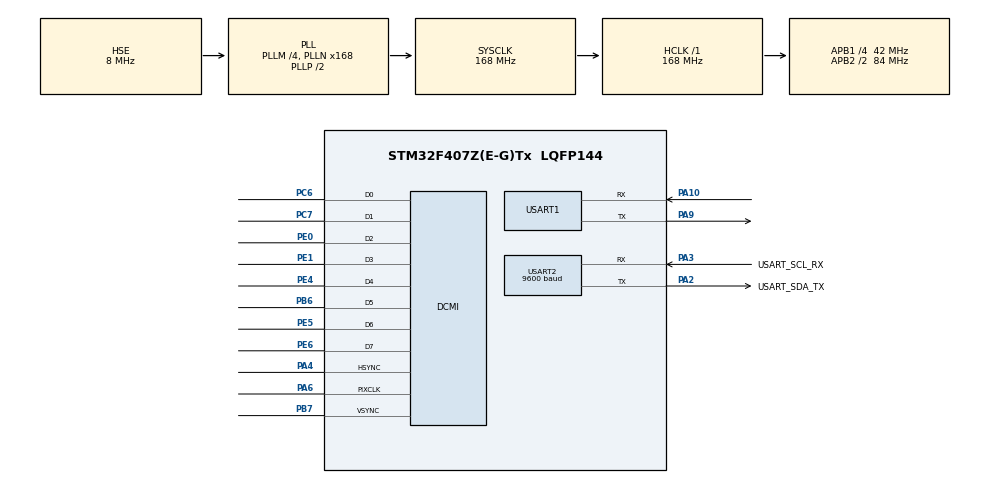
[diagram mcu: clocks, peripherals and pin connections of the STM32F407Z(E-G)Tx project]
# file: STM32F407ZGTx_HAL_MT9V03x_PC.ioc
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DCMI.JPEGMode=DCMI_JPEG_DISABLE
DCMI.PCKPolarity=DCMI_PCKPOLARITY_RISING
Dma.DCMI.0.Direction=DMA_PERIPH_TO_MEMORY
Dma.DCMI.0.FIFOMode=DMA_FIFOMODE_ENABLE
Dma.DCMI.0.FIFOThreshold=DMA_FIFO_THRESHOLD_FULL
Dma.DCMI.0.Instance=DMA2_Stream1
Dma.DCMI.0.MemBurst=DMA_MBURST_SINGLE
Dma.DCMI.0.MemDataAlignment=DMA_MDATAALIGN_WORD
Dma.DCMI.0.MemInc=DMA_MINC_ENABLE
Dma.DCMI.0.Mode=DMA_CIRCULAR
Dma.DCMI.0.PeriphBurst=DMA_PBURST_SINGLE
Dma.DCMI.0.PeriphDataAlignment=DMA_PDATAALIGN_WORD
Dma.DCMI.0.PeriphInc=DMA_PINC_DISABLE
Dma.DCMI.0.Priority=DMA_PRIORITY_VERY_HIGH
Dma.Request0=DCMI
Mcu.Family=STM32F4
Mcu.Name=STM32F407Z(E-G)Tx
Mcu.Package=LQFP144
NVIC.DCMI_IRQn=true\:0\:0\:false\:true\:true\:1\:true\:true\:true
NVIC.DMA2_Stream1_IRQn=true\:0\:0\:false\:false\:true\:false\:true\:true
NVIC.PriorityGroup=NVIC_PRIORITYGROUP_4
NVIC.USART2_IRQn=true\:0\:0\:false\:true\:true\:2\:true\:true\:true
PA10.Mode=Asynchronous
PA10.Signal=USART1_RX
PA13.Mode=Serial_Wire
PA13.Signal=SYS_JTMS-SWDIO
PA14.Mode=Serial_Wire
PA14.Signal=SYS_JTCK-SWCLK
PA2.GPIO_Label=USART_SDA_TX
PA2.Mode=Asynchronous
PA2.Signal=USART2_TX
PA3.GPIO_Label=USART_SCL_RX
PA3.Mode=Asynchronous
PA3.Signal=USART2_RX
PA4.Mode=Slave_8_bits_External_Synchro
PA4.Signal=DCMI_HSYNC
PA6.Mode=Slave_8_bits_External_Synchro
PA6.Signal=DCMI_PIXCLK
PA9.Mode=Asynchronous
PA9.Signal=USART1_TX
PB6.Mode=Slave_8_bits_External_Synchro
PB6.Signal=DCMI_D5
PB7.Mode=Slave_8_bits_External_Synchro
PB7.Signal=DCMI_VSYNC
PC14-OSC32_IN.Mode=LSE-External-Oscillator
PC14-OSC32_IN.Signal=RCC_OSC32_IN
PC15-OSC32_OUT.Mode=LSE-External-Oscillator
PC15-OSC32_OUT.Signal=RCC_OSC32_OUT
PC6.Mode=Slave_8_bits_External_Synchro
PC6.Signal=DCMI_D0
PC7.Mode=Slave_8_bits_External_Synchro
PC7.Signal=DCMI_D1
PE0.Mode=Slave_8_bits_External_Synchro
PE0.Signal=DCMI_D2
PE1.Mode=Slave_8_bits_External_Synchro
PE1.Signal=DCMI_D3
PE4.Mode=Slave_8_bits_External_Synchro
PE4.Signal=DCMI_D4
PE5.Mode=Slave_8_bits_External_Synchro
PE5.Signal=DCMI_D6
PE6.Mode=Slave_8_bits_External_Synchro
PE6.Signal=DCMI_D7
PH0-OSC_IN.Mode=HSE-External-Oscillator
PH0-OSC_IN.Signal=RCC_OSC_IN
PH1-OSC_OUT.Mode=HSE-External-Oscillator
PH1-OSC_OUT.Signal=RCC_OSC_OUT
ProjectManager.HeapSize=0x200
ProjectManager.StackSize=0x400
ProjectManager.TargetToolchain=MDK-ARM V5
RCC.48MHZClocksFreq_Value=84000000
RCC.AHBFreq_Value=168000000
RCC.APB1CLKDivider=RCC_HCLK_DIV4
RCC.APB1Freq_Value=42000000
RCC.APB1TimFreq_Value=84000000
RCC.APB2CLKDivider=RCC_HCLK_DIV2
RCC.APB2Freq_Value=84000000
RCC.APB2TimFreq_Value=168000000
RCC.CortexFreq_Value=168000000
RCC.HCLKFreq_Value=168000000
RCC.HSE_VALUE=8000000
RCC.HSI_VALUE=16000000
RCC.PLLM=4
RCC.PLLN=168
RCC.PLLSourceVirtual=RCC_PLLSOURCE_HSE
RCC.SYSCLKFreq_VALUE=168000000
RCC.SYSCLKSource=RCC_SYSCLKSOURCE_PLLCLK
RCC.VCOOutputFreq_Value=336000000
USART1.VirtualMode=VM_ASYNC
USART2.BaudRate=9600
USART2.VirtualMode=VM_ASYNC
board=custom

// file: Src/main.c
/* USER CODE BEGIN Header */
/**
  ******************************************************************************
  * @file           : main.c
  * @brief          : Main program body
  ******************************************************************************
  * @attention
  *
  * <h2><center>&copy; Copyright (c) 2019 STMicroelectronics.
  * All rights reserved.</center></h2>
  *
  * This software component is licensed by ST under BSD 3-Clause license,
  * the "License"; You may not use this file except in compliance with the
  * License. You may obtain a copy of the License at:
  *                        opensource.org/licenses/BSD-3-Clause
  *
  ******************************************************************************
  */
/* USER CODE END Header */
#include "main.h"
#include "dcmi.h"
#include "dma.h"
#include "usart.h"
#include "gpio.h"

/* USER CODE BEGIN Includes */
#include "SEEKFREE_MT9V03X.h"
#include "SEEKFREE_IIC.h"
/* USER CODE END Includes */

void SystemClock_Config(void);
static void MX_NVIC_Init(void);

/* USER CODE BEGIN 0 */

//printf重定向
int fputc(int ch,FILE *f)
{
    uint8_t temp[1]= {ch};
    HAL_UART_Transmit(&huart1,temp,1,0xFFFF);
    return 0;
}

/* USER CODE END 0 */

int main(void)
{

  /* MCU Configuration--------------------------------------------------------*/

  /* Reset of all peripherals, Initializes the Flash interface and the Systick. */
  HAL_Init();

  /* Configure the system clock */
  SystemClock_Config();

  /* Initialize all configured peripherals */
  MX_GPIO_Init();
  MX_DMA_Init();
  MX_DCMI_Init();
  MX_USART1_UART_Init();
  MX_USART2_UART_Init();

  /* Initialize interrupts */
  MX_NVIC_Init();
  /* USER CODE BEGIN 2 */

    // 由于本店并没有销售STM32相关的单片机已经核心板，提供这个例程仅仅是为了方便用户在32上使用而已，具体需要用户自己多多研究。
    // 由于本店并没有销售STM32相关的单片机已经核心板，提供这个例程仅仅是为了方便用户在32上使用而已，具体需要用户自己多多研究。
    // 由于本店并没有销售STM32相关的单片机已经核心板，提供这个例程仅仅是为了方便用户在32上使用而已，具体需要用户自己多多研究。
    while(mt9v03x_init())
    {
        // 初始化失败，带MCU的版本，请检查RX和TX引脚，是否连接正确。
        // 初始化失败，不带MCU的版本，请检查SCL和SDA引脚，是否连接正确。
    }
  /* USER CODE END 2 */

  /* Infinite loop */
  /* USER CODE BEGIN WHILE */

  while (1)
  {
	// 由于本店并没有销售STM32相关的单片机已经核心板，提供这个例程仅仅是为了方便用户在32上使用而已，具体需要用户自己多多研究。
    // 由于本店并没有销售STM32相关的单片机已经核心板，提供这个例程仅仅是为了方便用户在32上使用而已，具体需要用户自己多多研究。
    // 由于本店并没有销售STM32相关的单片机已经核心板，提供这个例程仅仅是为了方便用户在32上使用而已，具体需要用户自己多多研究。
	if(mt9v03x_finish_flag == 1)
	{
		seekfree_sendimg_mt9v03x(&huart1, mt9v03x_image, MT9V03X_IMAGE_SIZE);
		mt9v03x_finish_flag = 0;
	}
    /* USER CODE END WHILE */

  }
}

void SystemClock_Config(void)
{
  RCC_OscInitTypeDef RCC_OscInitStruct = {0};
  RCC_ClkInitTypeDef RCC_ClkInitStruct = {0};

  /** Configure the main internal regulator output voltage
  */
  __HAL_RCC_PWR_CLK_ENABLE();
  __HAL_PWR_VOLTAGESCALING_CONFIG(PWR_REGULATOR_VOLTAGE_SCALE1);

  /** Initializes the RCC Oscillators according to the specified parameters
  * in the RCC_OscInitTypeDef structure.
  */
  RCC_OscInitStruct.OscillatorType = RCC_OSCILLATORTYPE_HSE;
  RCC_OscInitStruct.HSEState = RCC_HSE_ON;
  RCC_OscInitStruct.PLL.PLLState = RCC_PLL_ON;
  RCC_OscInitStruct.PLL.PLLSource = RCC_PLLSOURCE_HSE;
  RCC_OscInitStruct.PLL.PLLM = 4;
  RCC_OscInitStruct.PLL.PLLN = 168;
  RCC_OscInitStruct.PLL.PLLP = RCC_PLLP_DIV2;
  RCC_OscInitStruct.PLL.PLLQ = 4;
  if (HAL_RCC_OscConfig(&RCC_OscInitStruct) != HAL_OK)
  {
    Error_Handler();
  }

  /** Initializes the CPU, AHB and APB buses clocks
  */
  RCC_ClkInitStruct.ClockType = RCC_CLOCKTYPE_HCLK|RCC_CLOCKTYPE_SYSCLK
                              |RCC_CLOCKTYPE_PCLK1|RCC_CLOCKTYPE_PCLK2;
  RCC_ClkInitStruct.SYSCLKSource = RCC_SYSCLKSOURCE_PLLCLK;
  RCC_ClkInitStruct.AHBCLKDivider = RCC_SYSCLK_DIV1;
  RCC_ClkInitStruct.APB1CLKDivider = RCC_HCLK_DIV4;
  RCC_ClkInitStruct.APB2CLKDivider = RCC_HCLK_DIV2;

  if (HAL_RCC_ClockConfig(&RCC_ClkInitStruct, FLASH_LATENCY_5) != HAL_OK)
  {
    Error_Handler();
  }
}

/**
  * @brief NVIC Configuration.
  * @retval None
  */
static void MX_NVIC_Init(void)
{
  /* DCMI_IRQn interrupt configuration */
  HAL_NVIC_SetPriority(DCMI_IRQn, 0, 0);
  HAL_NVIC_EnableIRQ(DCMI_IRQn);
  /* USART2_IRQn interrupt configuration */
  HAL_NVIC_SetPriority(USART2_IRQn, 0, 0);
  HAL_NVIC_EnableIRQ(USART2_IRQn);
}

void Error_Handler(void)
{
}
